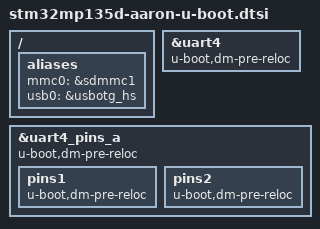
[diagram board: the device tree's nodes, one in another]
// SPDX-License-Identifier: (GPL-2.0-or-later OR BSD-3-Clause)
/*
 * Copyright (C) 2024, STMicroelectronics - All Rights Reserved
 * Author: STM32CubeMX code generation for STMicroelectronics.
 */

/* For more information on Device Tree configuration, please refer to
 * https://wiki.st.com/stm32mpu/wiki/Category:Device_tree_configuration
 */

#include "stm32mp13-u-boot.dtsi"

/ {
	aliases {
		mmc0 = &sdmmc1;
		usb0 = &usbotg_hs;
	};
};

&uart4 {
	u-boot,dm-pre-reloc;
};

&uart4_pins_a {
	u-boot,dm-pre-reloc;
	pins1 {
		u-boot,dm-pre-reloc;
	};
	pins2 {
		u-boot,dm-pre-reloc;
	};
};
